# R9A02G021 register map
Vendor: Renesas Electronics Corporation; Series: RISC-V; File version: 1.10.00 + 202304131714_CPU
CPU: other r0p0, little endian, no MPU, no FPU, VTOR, 4 interrupt priority bits, 32 interrupts
Registers are 8-bit, read-write, reset 0x0 unless marked. A register's access mark holds for its fields unless they carry their own. Offsets are from the block's base; [hi:lo] are bit positions; {n}, {i} and the like mark numbered series; 'fields as' and 'values as' point back to an identical list.

## MSTP — Module Stop Control B, C, D
Base 0x40047000
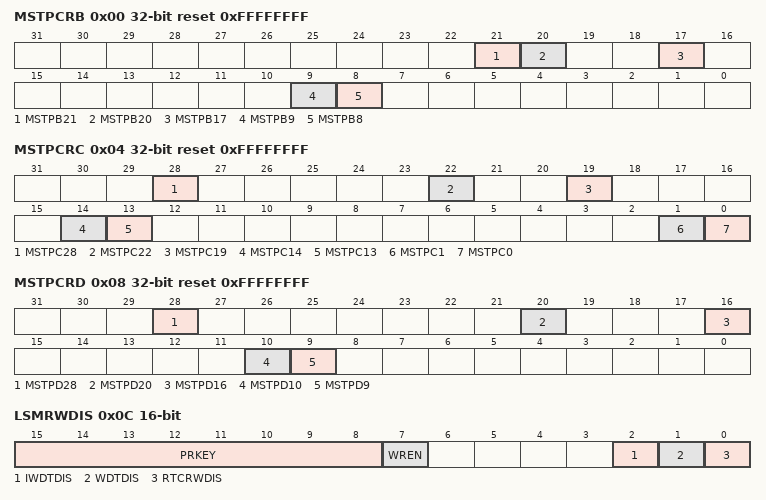
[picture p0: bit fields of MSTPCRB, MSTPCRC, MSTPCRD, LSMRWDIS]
0x00 MSTPCRB 32-bit reset 0xFFFFFFFF — Module Stop Control Register B
  [all] fields
    0=Cancel the module-stop state; 1=Enter the module-stop state
  [21] MSTPB21 — Serial Array Unit 0 Module Stop
  [20] MSTPB20 — Serial Array Unit 1 Module Stop
  [17] MSTPB17 — Serial Interface UARTA0/UARTA1 Module Stop
  [9] MSTPB9 — I2C Bus Interface 0 Module Stop
  [8] MSTPB8 — I2C Bus Interface 1 Module Stop
0x04 MSTPCRC 32-bit reset 0xFFFFFFFF — Module Stop Control Register C
  [all] fields
    values as the fields of MSTPCRB
  [28] MSTPC28 — True Random Number Generator Module Stop
  [22] MSTPC22 — 8-bit D/A Converter Module Stop
  [19] MSTPC19 — Remote Control Signal Receiver Module Stop
  [14] MSTPC14 — Event Link Controller Module Stop
  [13] MSTPC13 — Data Operation Circuit Module Stop
  [1] MSTPC1 — Cyclic Redundancy Check Calculator Module Stop
  [0] MSTPC0 — Clock Frequency Accuracy Measurement Circuit Module Stop
0x08 MSTPCRD 32-bit reset 0xFFFFFFFF — Module Stop Control Register D
  [all] fields
    values as the fields of MSTPCRB
  [28] MSTPD28 — Comparator Module Stop
  [20] MSTPD20 — 8-bit D/A Converter Module Stop
  [16] MSTPD16 — 12-bit A/D Converter Module Stop
  [10] MSTPD10 — Timer Array Unit Module Stop
  [9] MSTPD9 — 32-bit Interval Timer Module Stop
0x0C LSMRWDIS 16-bit — Low Speed Module R/W Disable Control Register
  [15:8] PRKEY wo — LSMRWDIS Key Code
  [7] WREN — Write Enable for bits [2:0]
    0=Write protect for bits [2:0]; 1=Write enable for bits [2:0]
  [2] IWDTDIS — IWDT Register Clock Control
    0=IWDT operates as normal; 1=Stop the IWDT register R/W clock
  [1] WDTDIS — WDT Operate Clock Control
    0=WDT operates as normal; 1=Stop the WDT clock and register R/W clock
  [0] RTCRWDIS — RTC Register R/W Enable Control
    0=RTC register R/W clock always on; 1=RTC register R/W clock stops

## DAC8 — 8-bit D/A converter
Base 0x4005E000
{0x0+2i} DADR{i} (i=0..1) 16-bit — D/A Data Register {i}
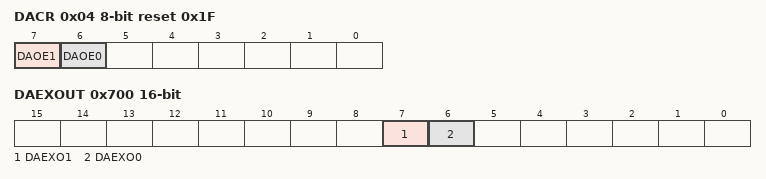
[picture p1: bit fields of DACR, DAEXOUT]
0x04 DACR reset 0x1F — D/A Control Register
  [7] DAOE1 — D/A Output Enable 1
    0=Analog output of channel 1 (DA1) is disabled; 1=D/A conversion of channel 1 is enabled. Analog output of channel 1 (DA1) is enabled.
  [6] DAOE0 — D/A Output Enable 0
    0=Analog output of channel 0 (DA0) is disabled; 1=D/A conversion of channel 0 is enabled. Analog output of channel 0 (DA0) is enabled.
0x05 DADPR — DADRn Format Select Register
  [7] DPSEL — DADRn Format Select
    0=Right-justified format; 1=Left-justified format
0x700 DAEXOUT 16-bit — D/A External Output Enable Register
  [7] DAEXO1 — D/A External Pin Output Enable 1
    0=DA1 output to DACOUT1 pin is disabled; 1=DA1 output to DACOUT1 pin is enabled
  [6] DAEXO0 — D/A External Pin Output Enable 0
    0=DA0 output to DACOUT0 pin is disabled; 1=DA0 output to DACOUT0 pin is enabled

## CRC — Cyclic Redundancy Check Calculator
Base 0x40074000
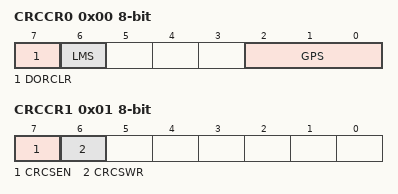
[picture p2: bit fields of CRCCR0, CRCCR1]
0x00 CRCCR0 — CRC Control Register 0
  [7] DORCLR wo — CRCDOR/CRCDOR_HA/CRCDOR_BY Register Clear
    0=No effect; 1=Clear the CRCDOR/CRCDOR_HA/CRCDOR_BY register
  [6] LMS — CRC Calculation Switching
    0=Generate CRC code for LSB-first communication; 1=Generate CRC code for MSB-first communication
  [2:0] GPS — CRC Generating Polynomial Switching
    1=8-bit CRC-8 (X8 + X2 + X + 1); 2=16-bit CRC-16 (X16 + X15 + X2 + 1); 3=16-bit CRC-CCITT (X16 + X12 + X5 + 1); 4=32-bit CRC-32 (X32 + X26 + X23 + X22 + X16 + X12 + X11 +X10 + X8 + X7 + X5 + X4 + X2 + X + 1); 5=32-bit CRC-32C (X32 + X28 + X27 + X26 + X25 + X23 + X22 + X20 + X19 + X18 + X14 + X13 + X11 + X10 + X9 + X8 + X6 + 1); other=Others (No calculation is executed)
0x01 CRCCR1 — CRC Control Register 1
  [7] CRCSEN — Snoop Enable
    0=Disabled; 1=Enabled
  [6] CRCSWR — Snoop-On-Write/Read Switch
    0=Snoop-on-read; 1=Snoop-on-write
0x04 CRCDIR 32-bit — CRC Data Input Register
0x04 CRCDIR_BY (alternate view of CRCDIR) — CRC Data Input Register
0x08 CRCDOR 32-bit — CRC Data Output Register
0x08 CRCDOR_HA 16-bit (alternate view of CRCDOR) — CRC Data Output Register
0x08 CRCDOR_BY (alternate view of CRCDOR) — CRC Data Output Register
0x0C CRCSAR 16-bit — Snoop Address Register
  [13:0] CRCSA — Register Snoop Address
